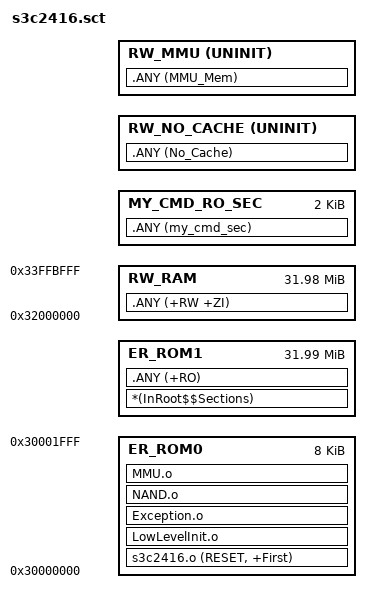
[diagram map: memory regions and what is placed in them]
; *************************************************************
; *** Scatter-Loading Description File generated by uVision ***
; *************************************************************
/*
LR_IROM1 0x30000000   {    ; load region size_region
; 启动代码8k在steppingstone中执行,启动代码相关的代码必须链接在8k范围
; 内,并且是与地址无关的,可链接到任意地址
  ER_ROM1 0x30000000 0x2000000 {  
   *(InRoot$$Sections) 
   .ANY (+RO)    
  }
  RW_RAM +0 0x2000000-0x4000-0x4000-0x2000  {  ; RW data
   .ANY (+RW +ZI) 
  }
; RAM的最后24k分配给MMU页表和bootloader
; MMU页表在编译器初始化代码之前调用分配初始化,一定不应再让编译器初始化
  RW_MMU +0 0x4000+0x4000 { ; ZI data does not get initialized to zero
   .ANY (MMU_Mem)
  }
  ER_ROM0 +0 0x2000 {  ; load address = execution address 
   s3c2416.o (RESET, +First)
   LowLevelInit.o
   Exception.o
   NAND.o   
   MMU.o
  }
}
*/

; *************************************************************
; *** Scatter-Loading Description File generated by uVision ***
; *************************************************************

LR_IROM1 0x30000000   {    ; load region size_region
; 启动代码8k在steppingstone中执行,启动代码相关的代码必须链接在8k范围
; 内,并且是与地址无关的,可链接到任意地址
  ER_ROM0 0x30000000 0x2000 {  ; load address = execution address 
   s3c2416.o (RESET, +First)
   LowLevelInit.o
   Exception.o
   NAND.o   
   MMU.o
  }
  ER_ROM1 +0 0x2000000-0x2000 {  
   *(InRoot$$Sections) 
   .ANY (+RO)    
  }
  RW_RAM 0x32000000 0x2000000-0x4000  {  ; RW data
   .ANY (+RW +ZI) 
  }
    
; 分配命令存储空间
  MY_CMD_RO_SEC +0 0x800 {
   .ANY (my_cmd_sec)
  }
; 分配关闭cache的内存空间,作为DMA使用的内存段,如LCD帧缓存,IIS DMA
; 传输等,DMA直接访问主存,为保证数据的一至性,cpu对DMA共同访问的内存区域
; 也应关闭cache,保证cpu每次都访问主存,虽降低性能,但主存数据一直是最新的
; 这段内存在MMU中设置不可cache,1M对齐
  RW_NO_CACHE AlignExpr(+0, 0x100000) UNINIT {
   .ANY (No_Cache)
  }
; 不用初始化变量
;  RW_NO_INIT +0 UNINIT { ; ZI data does not get initialized to zero
;   .ANY (No_Init_Data)
;  }
; RAM的最后16k分配给MMU页表 
; MMU页表在编译器初始化代码之前调用分配初始化,一定不应再让编译器初始化
  RW_MMU +0 UNINIT { ; ZI data does not get initialized to zero
   .ANY (MMU_Mem)
  }
}


